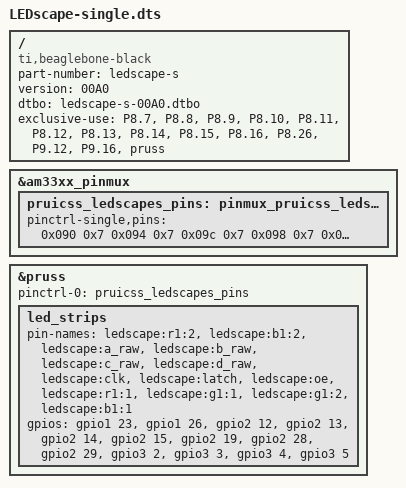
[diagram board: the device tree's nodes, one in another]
/** \file
 * Try to play nice with the Beagle Bone device tree.
 *
 * But it really sucks.  This is a waste of time; we can just use
 * a shell script to poke the gpio export and config files since this
 * is so borked.
 */
/dts-v1/;
/plugin/;

/ {
    compatible = "ti,beaglebone-black";

    /* identification */
    part-number = "ledscape-s";
    version = "00A0";
    dtbo = "ledscape-s-00A0.dtbo";

    /* state the resources this cape uses or prepare to get winged! */
    exclusive-use =
        /* 6*1 bank(s) + 7 control = 13 IO pins for the PRU to use */
        "P8.7",  "P8.8",
	    "P8.9",  "P8.10",
	    "P8.11", "P8.12",
	    "P8.13", "P8.14",
	    "P8.15", "P8.16",
	             "P8.26",

	             "P9.12",
	             "P9.16",

	    // And we need the PRU
        "pruss"; 

    fragment@0 {
        target = <&am33xx_pinmux>;
        __overlay__ {
            pruicss_ledscapes_pins: pinmux_pruicss_ledscapes_pins {
		        // Mode 7 is GPIO output
                pinctrl-single,pins = <
			        0x090 0x7 // P8.7 gpio2.2 - R1.1
			        0x094 0x7 // P8.8 gpio2.3 - G1.1
			        0x09c 0x7 // P8.9 gpio2.5 - B1.1
			        0x098 0x7 // P8.10 gpio2.4 - G1.2
			        0x034 0x7 // P8.11 gpio1.13 - B_RAW
			        0x030 0x7 // P8.12 gpio1.12 - A_RAW
			        0x024 0x7 // P8.13 gpio0.23 - R1.2
			        0x028 0x7 // P8.14 gpio0.26 - B1.2
			        0x03c 0x7 // P8.15 gpio1.15 - D_RAW
			        0x038 0x7 // P8.16 gpio1.14 - C_RAW
			        0x07c 0x7 // P8.26 gpio1.29 - OE

			        0x078 0x7 // P9.12 gpio1.28 - LATCH
			        0x04c 0x7 // P9.16 gpio1.19 - CLK
                >;
            };
        };
    };

    fragment@1 {
        target = <&pruss>;
        __overlay__{
            status = "okay";
            pinctrl-names = "default";
            pinctrl-0 = <&pruicss_ledscapes_pins>;
	        led_strips {
                pin-names     =
			        "ledscape:r1:2",
			        "ledscape:b1:2",
			        "ledscape:a_raw",
			        "ledscape:b_raw",
			        "ledscape:c_raw",
			        "ledscape:d_raw",
			        "ledscape:clk",
			        "ledscape:latch",
			        "ledscape:oe",
			        "ledscape:r1:1",
			        "ledscape:g1:1",
			        "ledscape:g1:2",
			        "ledscape:b1:1";

                /* gpio0 --> gpio1 in DT */
                gpios         = <
                    &gpio1 23 0
                    &gpio1 26 0
                    &gpio2 12 0
                    &gpio2 13 0
                    &gpio2 14 0
                    &gpio2 15 0
                    &gpio2 19 0
                    &gpio2 28 0
                    &gpio2 29 0
                    &gpio3 2 0
                    &gpio3 3 0
                    &gpio3 4 0
                    &gpio3 5 0
                >;
            };
        };
    };
};
